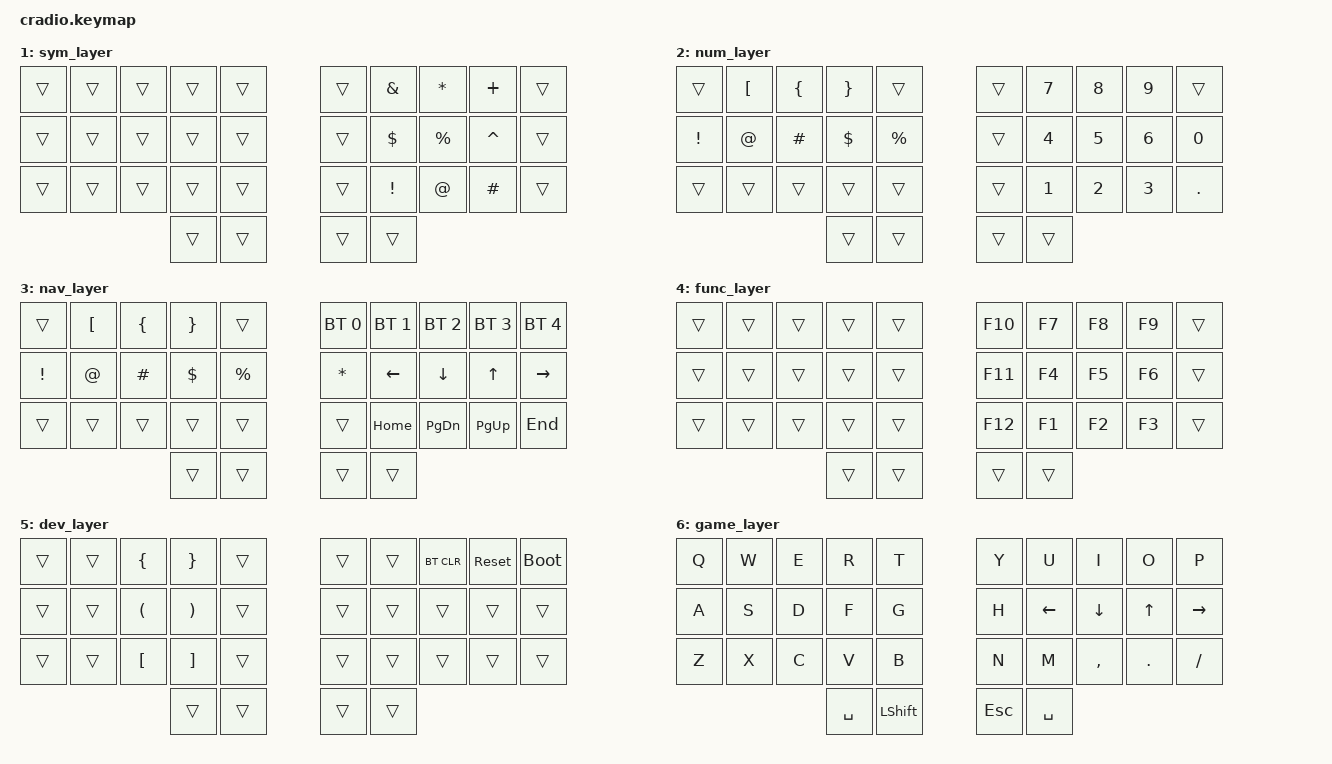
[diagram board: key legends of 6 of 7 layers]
// Copyright (c) 2022 The ZMK Contributors
// SPDX-License-Identifier: MIT
#include "includes/keypos_34keys.h"

#include <behaviors.dtsi>
#include <dt-bindings/zmk/keys.h>
#include <dt-bindings/zmk/bt.h>

#define DEF  0
#define SYM  1
#define NUM  2
#define NAV  3
#define FUNC 4
#define DEV  5
#define GAME 6

/* keypos definitions */
#define KEYS_L LT0 LT1 LT2 LT3 LT4 LM0 LM1 LM2 LM3 LM4 LB0 LB1 LB2 LB3 LB4
#define KEYS_R RT0 RT1 RT2 RT3 RT4 RM0 RM1 RM2 RM3 RM4 RB0 RB1 RB2 RB3 RB4
#define KEYS_T  LH1 LH0 RH0 RH1 


// My imports
#include "includes/behaviours_homerow_mods.dtsi"

// ─────────────────────────────────────────────────────────────
// Home Row Mod Macros
// ─────────────────────────────────────────────────────────────
#define HRML(k1, k2, k3, k4) &gui LGUI  k1 &ring_mod LALT k2 &middle_mod LCTRL  k3 &index_mod LSHFT k4
#define HRMR(k1, k2, k3, k4) &index_mod RSHFT  k1 &middle_mod RCTRL k2 &ring_mod RALT  k3 &gui RGUI k4

#define HM_TAPPING_TERM 300
#define HM_TAPPING_TERM_FAST 200
#define HM_PRIOR_IDLE 150

/ {
  // ───────────────────────────────────────────────────────────
  // Behaviors
  // ───────────────────────────────────────────────────────────
  behaviors {
    ht: hold_tap {
    compatible = "zmk,behavior-hold-tap";
    #binding-cells = <2>;
    flavor = "tap-preferred";
    tapping-term-ms = <220>;
    quick-tap-ms = <150>;
    require-prior-idle-ms = <100>;
    bindings = <&kp>, <&kp>;
  };

      


  
  };

 
  // ───────────────────────────────────────────────────────────
  // Combos
  // ───────────────────────────────────────────────────────────
  combos {
    compatible = "zmk,combos";

    combo_apos  { timeout-ms = <30>; key-positions = <17 18>; bindings = <&kp APOS>;   };
    combo_dash  { timeout-ms = <30>; key-positions = <7 8>;   bindings = <&kp MINUS>;  };
    combo_esc   { timeout-ms = <30>; key-positions = <26 27>; bindings = <&kp ESC>;    };
    combo_del   { timeout-ms = <30>; key-positions = <32 33>; bindings = <&kp DEL>;    };
    combo_dqt   { timeout-ms = <30>; key-positions = <11 12>; bindings = <&kp DQT>;    };
    combo_pipe  { timeout-ms = <30>; key-positions = <21 22>; bindings = <&kp PIPE>;   };
    combo_bslh  { timeout-ms = <30>; key-positions = <27 28>; bindings = <&kp BSLH>;   };
    combo_tilde { timeout-ms = <30>; key-positions = <6 7>;   bindings = <&kp TILDE>;  };
    combo_grave { timeout-ms = <30>; key-positions = <2 3>;   bindings = <&kp GRAVE>;  };
    combo_under { timeout-ms = <30>; key-positions = <1 2>;   bindings = <&kp UNDER>;  };
    combo_plus  { timeout-ms = <30>; key-positions = <12 13>; bindings = <&kp PLUS>;   };
    combo_equal { timeout-ms = <30>; key-positions = <16 17>; bindings = <&kp EQUAL>;  };
    combo_nav   { timeout-ms = <30>; key-positions = <22 23>; bindings = <&mo NAV>;    };
    combo_enter { timeout-ms = <30>; key-positions = <16 17 18>; bindings = <&kp ENTER>; };   
    combo_game { timeout-ms = <30>; key-positions = <9 19 29>; bindings = <&tog GAME>; };
    copy_combo { timeout-ms = <50>; key-positions = <20 11>; bindings = <&kp LC(C)>;   };
    paste_combo { timeout-ms = <50>; key-positions = <12 23>; bindings = <&kp LC(V)>;   };



  };

  // ───────────────────────────────────────────────────────────
  // Keymap Layers
  // ───────────────────────────────────────────────────────────
  keymap {
    compatible = "zmk,keymap";
  

    // ╭───────────────────────────────╮
    // │ Default Layer                │
    // ╰───────────────────────────────╯
    def_layer {
      bindings = <
        &kp Q    &kp W    &kp F    &kp P    &kp B          &kp J    &kp L    &kp U    &kp Y     &kp SEMI
        HRML(A,R,S,T)                  &kp G               &kp M       HRMR(N,E,I,O)
        &kp Z    &kp X    &kp C    &kp D    &kp V          &kp K    &kp H    &kp COMMA &kp DOT   &kp FSLH
                        &lt SYM  TAB   &lt NUM ENTER       &lt DEV SPACE  &kp BSPC
      >;
    };

    // ╭───────────────────────────────╮
    // │ Symbol Layer                 │
    // ╰───────────────────────────────╯
    sym_layer {
      bindings = <
        &trans   &trans   &trans   &trans   &trans         &trans     &kp AMPS   &kp ASTRK  &kp PLUS   &trans
        &trans   &trans   &trans   &trans   &trans         &trans     &kp DLLR   &kp PRCNT  &kp CARET  &trans
        &trans   &trans   &trans   &trans   &trans         &trans     &kp EXCL   &kp AT     &kp HASH   &trans
                                &trans     &trans         &trans     &trans
      >;
    };

    // ╭───────────────────────────────╮
    // │ Number Layer                 │
    // ╰───────────────────────────────╯
    num_layer {
      bindings = <
        &trans   &kp LBKT &kp LBRC &kp RBRC &trans         &trans     &kp N7     &kp N8     &kp N9     &trans
        &kp EXCL &kp AT   &kp HASH &kp DLLR &kp PRCNT      &trans     &kp N4     &kp N5     &kp N6     &kp N0
        &trans   &trans   &trans   &trans   &trans         &trans     &kp N1     &kp N2     &kp N3     &kp DOT
                                &trans     &trans         &trans     &trans
      >;
    };

    // ╭───────────────────────────────╮
    // │ Navigation Layer             │
    // ╰───────────────────────────────╯
    nav_layer {
      bindings = <
        &trans   &kp LBKT &kp LBRC &kp RBRC &trans         &bt BT_SEL 0  &bt BT_SEL 1  &bt BT_SEL 2  &bt BT_SEL 3  &bt BT_SEL 4
        &kp EXCL &kp AT   &kp HASH &kp DLLR &kp PRCNT      &kp ASTRK     &kp LEFT      &kp DOWN      &kp UP        &kp RIGHT
        &trans   &trans   &trans   &trans   &trans         &trans    &kp HOME      &kp PG_DN     &kp PG_UP     &kp END
                                &trans     &trans          &trans    &trans
      >;
    };

    // ╭───────────────────────────────╮
    // │ Function Layer               │
    // ╰───────────────────────────────╯
    func_layer {
      bindings = <
        &trans   &trans   &trans   &trans   &trans         &kp F10  &kp F7  &kp F8  &kp F9  &trans
        &trans   &trans   &trans   &trans   &trans         &kp F11  &kp F4  &kp F5  &kp F6  &trans
        &trans   &trans   &trans   &trans   &trans         &kp F12  &kp F1  &kp F2  &kp F3  &trans
                                &trans     &trans         &trans   &trans
      >;
    };

    // ╭───────────────────────────────╮
    // │ Developer Layer              │
    // ╰───────────────────────────────╯
    dev_layer {
      bindings = <
        &trans   &trans   &kp LBRC &kp RBRC &trans         &trans   &trans   &bt BT_CLR   &sys_reset   &bootloader
        &trans   &trans   &kp LPAR &kp RPAR &trans         &trans   &trans   &trans   &trans   &trans
        &trans   &trans   &kp LBKT &kp RBKT &trans         &trans   &trans   &trans   &trans   &trans
                                &trans     &trans         &trans   &trans
      >;
    };

    // ╭───────────────────────────────╮
    // │ Gaming Layer                 │
    // ╰───────────────────────────────╯
    game_layer {
      bindings = <
        &kp Q    &kp W    &kp E    &kp R    &kp T          &kp Y    &kp U    &kp I    &kp O     &kp P
        &kp A    &kp S    &kp D    &kp F    &kp G          &kp H    &kp LEFT  &kp DOWN &kp UP &kp RIGHT
        &kp Z    &kp X    &kp C    &kp V    &kp B          &kp N    &kp M    &kp COMMA &kp DOT   &kp FSLH
                           &kp SPACE      &kp LSHFT        &kp ESC  &kp SPACE
      >;
    };
  };
};
